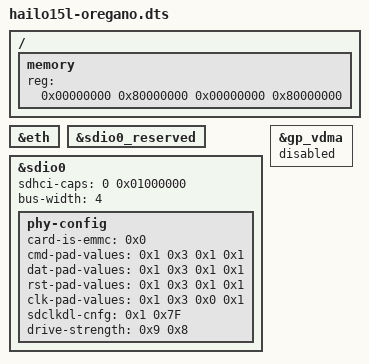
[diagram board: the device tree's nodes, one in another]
// SPDX-License-Identifier:     GPL-2.0
/*
 * Copyright (c) 2019-2024 Hailo Technologies Ltd. All rights reserved.
 */

/dts-v1/;
#include "hailo15l-base.dtsi"

/ {
    memory {
        device_type = "memory";
        reg = <0x00000000 0x80000000 0x00000000 0x80000000>;
    };
};

&eth {
    status = "okay";
};

&sdio0_reserved {
    status = "okay";
};
&sdio0 {
    status = "okay";
    sdhci-caps = <0 0x01000000>; // Force VOLT33 capability
    bus-width = <4>;

    phy-config {
            card-is-emmc = <0x0>;
            cmd-pad-values = <0x1 0x3 0x1 0x1>; // txslew_ctrl_n, txslew_ctrl_p, weakpull_enable, rxsel
            dat-pad-values = <0x1 0x3 0x1 0x1>; // txslew_ctrl_n, txslew_ctrl_p, weakpull_enable, rxsel
            rst-pad-values = <0x1 0x3 0x1 0x1>; // txslew_ctrl_n, txslew_ctrl_p, weakpull_enable, rxsel
            clk-pad-values = <0x1 0x3 0x0 0x1>; // txslew_ctrl_n, txslew_ctrl_p, weakpull_enable, rxsel
            sdclkdl-cnfg = <0x1 0x7F>; //extdly_en, cckdl_dc
            drive-strength = <0x9 0x8>; //pad_sp, pad_sn
    };
};

&gp_vdma {
    status = "disabled";
};

/delete-node/ &cpu_1;
/delete-node/ &cpu_2;
/delete-node/ &cpu_3;
